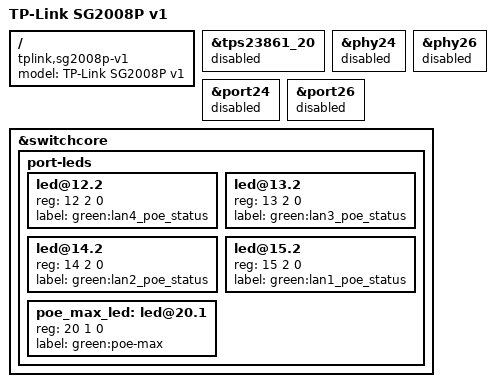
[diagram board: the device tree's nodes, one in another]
// SPDX-License-Identifier: GPL-2.0-or-later

#include "rtl8380_tplink_sg2xxx.dtsi"

/ {
	compatible = "tplink,sg2008p-v1", "realtek,rtl838x-soc";
	model = "TP-Link SG2008P v1";
};

&tps23861_20 {
	status = "disabled";
};

&phy24 {
	status = "disabled";
};

&phy26 {
	status = "disabled";
};

&port24 {
	status = "disabled";
};

&port26 {
	status = "disabled";
};

&switchcore {
	port-leds {
		led@12.2 {
			reg = <12 2 0>;
			label = "green:lan4_poe_status";
		};
		led@13.2 {
			reg = <13 2 0>;
			label = "green:lan3_poe_status";
		};
		led@14.2 {
			reg = <14 2 0>;
			label = "green:lan2_poe_status";
		};
		led@15.2 {
			reg = <15 2 0>;
			label = "green:lan1_poe_status";
		};

		poe_max_led: led@20.1 {
			reg = <20 1 0>;
			label = "green:poe-max";
		};
	};
};
